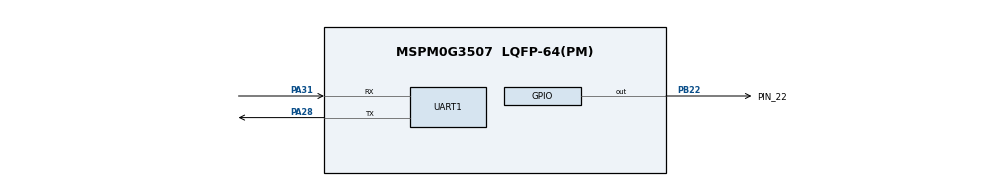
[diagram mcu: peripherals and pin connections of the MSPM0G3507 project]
/**
 * These arguments were used when this file was generated. They will be automatically applied on subsequent loads
 * via the GUI or CLI. Run CLI with '--help' for additional information on how to override these arguments.
 * @cliArgs --device "MSPM0G350X" --part "Default" --package "LQFP-64(PM)" --product "mspm0_sdk@2.05.01.00"
 * @v2CliArgs --device "MSPM0G3507" --package "LQFP-64(PM)" --product "mspm0_sdk@2.05.01.00"
 * @versions {"tool":"1.24.0+4110"}
 */

/**
 * Import the modules used in this configuration.
 */
const GPIO   = scripting.addModule("/ti/driverlib/GPIO", {}, false);
const GPIO1  = GPIO.addInstance();
const SYSCTL = scripting.addModule("/ti/driverlib/SYSCTL");
const UART   = scripting.addModule("/ti/driverlib/UART", {}, false);
const UART1  = UART.addInstance();

/**
 * Write custom configuration values to the imported modules.
 */
const divider9       = system.clockTree["UDIV"];
divider9.divideValue = 2;

const gate7  = system.clockTree["MFCLKGATE"];
gate7.enable = true;

const mux4       = system.clockTree["EXHFMUX"];
mux4.inputSelect = "EXHFMUX_XTAL";

const mux8       = system.clockTree["HSCLKMUX"];
mux8.inputSelect = "HSCLKMUX_SYSPLL2X";

const mux12       = system.clockTree["SYSPLLMUX"];
mux12.inputSelect = "zSYSPLLMUX_HFCLK";

const pinFunction4       = system.clockTree["HFXT"];
pinFunction4.inputFreq   = 40;
pinFunction4.enable      = true;
pinFunction4.HFXTStartup = 10;

GPIO1.port                          = "PORTB";
GPIO1.$name                         = "GPIO_GRP_B";
GPIO1.associatedPins[0].$name       = "PIN_22";
GPIO1.associatedPins[0].assignedPin = "22";
GPIO1.associatedPins[0].pin.$assign = "PB22";

const Board = scripting.addModule("/ti/driverlib/Board", {}, false);

SYSCTL.forceDefaultClkConfig = true;
SYSCTL.clockTreeEn           = true;
scripting.suppress("For best practices when the CPUCLK is running at 32MHz and above, clear the flash status bit using DL_FlashCTL_executeClearStatus\\(\\) before executing any flash operation\\. Otherwise there may be false positives\\.", SYSCTL);

UART1.$name                             = "UART_0";
UART1.targetBaudRate                    = 100000;
UART1.uartClkSrc                        = "MFCLK";
UART1.enableFIFO                        = true;
UART1.rxFifoThreshold                   = "DL_UART_RX_FIFO_LEVEL_ONE_ENTRY";
UART1.enabledDMARXTriggers              = "DL_UART_DMA_INTERRUPT_RX";
UART1.txFifoThreshold                   = "DL_UART_TX_FIFO_LEVEL_ONE_ENTRY";
UART1.enabledDMATXTriggers              = "DL_UART_DMA_INTERRUPT_TX";
UART1.enabledInterrupts                 = ["DMA_DONE_RX","DMA_DONE_TX","EOT_DONE","RX_TIMEOUT_ERROR"];
UART1.peripheral.$assign                = "UART0";
UART1.peripheral.rxPin.$assign          = "PA31";
UART1.peripheral.txPin.$assign          = "PA28";
UART1.txPinConfig.$name                 = "ti_driverlib_gpio_GPIOPinGeneric0";
UART1.rxPinConfig.$name                 = "ti_driverlib_gpio_GPIOPinGeneric1";
UART1.DMA_CHANNEL_RX.$name              = "DMA_CH0";
UART1.DMA_CHANNEL_RX.addressMode        = "f2b";
UART1.DMA_CHANNEL_RX.srcLength          = "BYTE";
UART1.DMA_CHANNEL_RX.dstLength          = "BYTE";
UART1.DMA_CHANNEL_RX.peripheral.$assign = "DMA_CH0";
UART1.DMA_CHANNEL_TX.$name              = "DMA_CH1";
UART1.DMA_CHANNEL_TX.addressMode        = "b2f";
UART1.DMA_CHANNEL_TX.srcLength          = "BYTE";
UART1.DMA_CHANNEL_TX.dstLength          = "BYTE";

/**
 * Pinmux solution for unlocked pins/peripherals. This ensures that minor changes to the automatic solver in a future
 * version of the tool will not impact the pinmux you originally saw.  These lines can be completely deleted in order to
 * re-solve from scratch.
 */
pinFunction4.peripheral.$suggestSolution           = "SYSCTL";
pinFunction4.peripheral.hfxInPin.$suggestSolution  = "PA5";
pinFunction4.peripheral.hfxOutPin.$suggestSolution = "PA6";
Board.peripheral.$suggestSolution                  = "DEBUGSS";
Board.peripheral.swclkPin.$suggestSolution         = "PA20";
Board.peripheral.swdioPin.$suggestSolution         = "PA19";
UART1.DMA_CHANNEL_TX.peripheral.$suggestSolution   = "DMA_CH1";
